# control_module register map
Vendor: Texas Instruments
Peripheral module from a debugger description file (folder am335x).
Registers are 32-bit, access per field, no defined reset value unless marked. A register's access mark holds for its fields unless they carry their own. Offsets are as the file gives them; lines under a group give offsets from that group; [hi:lo] are bit positions; {n}, {i} and the like mark numbered series; 'fields as' and 'values as' point back to an identical list; <NAME> marks a mode.

## CONTROL_MODULE (part 1 of 3)
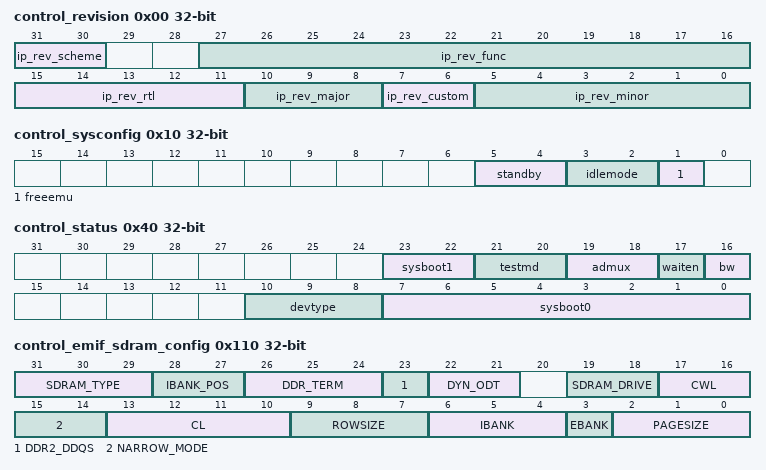
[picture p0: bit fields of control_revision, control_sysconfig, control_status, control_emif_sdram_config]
0x00 control_revision ro
  [31:30] ip_rev_scheme — 01 - New Scheme
  [27:16] ip_rev_func — Function indicates a software compatible module family. If there is no level of software compatibility a new Func number (and hence REVISION) should be assigned.
  [15:11] ip_rev_rtl — RTL Version (R).
  [10:8] ip_rev_major — Major Revision (X).
  [7:6] ip_rev_custom — Indicates a special version for a particular device. Consequence of use may avoid use of standard Chip Support Library (CSL) / Drivers - 00 = Non custom (standard) revision
  [5:0] ip_rev_minor — Minor Revision (Y).
0x04 control_hwinfo ro
  [31:0] ip_hwinfo — IP Module dependent
0x10 control_sysconfig
  [5:4] standby ro — Configure local initiator state management. Reserved in Control Module since it has no local initiator.
  [3:2] idlemode rw — Configure local target state management.
  [1] freeemu ro — Sensitivity to Emulation suspend input.
    1=en_2_0x1 (Module not sensitive to EMU suspend); 0=en_1_0x0 (Module is sensitive to EMU suspend)
0x40 control_status
  [23:22] sysboot1 rw — Used to select crystal clock frequency. See SYSBOOT Configuration Pins. Reset value is from SYSBOOT[15:14].
  [21:20] testmd rw — Set to 00b. See SYSBOOT Configuration Pins for more information. Reset value is from SYSBOOT[13:12].
  [19:18] admux rw — GPMC CS0 Default Address Muxing Reset value is from SYSBOOT[11:10].
  [17] waiten rw — GPMC CS0 Default Wait Enable See SYSBOOT Configuration Pins for more information. Reset value is from SYSBOOT[9].
    1=en_2_0x1 (Use WAIT input); 0=en_1_0x0 (Ignore WAIT input)
  [16] bw rw — GPMC CS0 Default Bus Width See SYSBOOT Configuration Pins for more information. Reset value is from SYSBOOT[8].
    1=en_2_0x1 (16-bit data bus); 0=en_1_0x0 (8-bit data bus)
  [10:8] devtype ro
  [7:0] sysboot0 rw — Selected boot mode. See SYSBOOT Configuration Pins for more information. Reset value is from SYSBOOT[7:0].
0x110 control_emif_sdram_config — The CONTROL_EMIF_SDRAM_CONFIG register exports SDRAM configuration information to the EMIF after resuming from low power scenarios. This register should be loaded with the same value as SDRAM_CONFIG during DDR initialization.
  [31:29] SDRAM_TYPE rw — SDRAM Type selection
  [28:27] IBANK_POS rw — Internal bank position.
  [26:24] DDR_TERM rw — DDR2 and DDR3 termination resistor value. Set to 0 to disable termination. For DDR2, set to 1 for 75 ohm, set to 2 for 150 ohm, and set to 3 for 50 ohm. For DDR3, set to 1 for RZQ/4, set to 2 for RZQ/2, set to 3 for RZQ/6, set to 4 for RZQ/12, and set to 5 for RZQ/8. All other values are reserved.
  [23] DDR2_DDQS rw — DDR2 differential DQS enable. Set to 0 for single ended DQS. Set to 1 for differential DQS
  [22:21] DYN_ODT rw — DDR3 Dynamic ODT. Set to 0 to turn off dynamic ODT. Set to 1 for RZQ/4 and set to 2 for RZQ/2. All other values are reserved.
  [19:18] SDRAM_DRIVE rw — SDRAM drive strength. For DDR2, set to 0 for normal, and set to 1 for weak drive strength. For DDR3, set to 0 for RZQ/6 and set to 1 for RZQ/7. For LPDDR1, set to 0 for full, set to 1 for 1/2, set to 2 for 1/4, and set to 3 for 1/8 drive strength. All other values are reserved.
  [17:16] CWL rw — DDR3 CAS Write latency. Value of 0, 1, 2, and 3 (CAS write latency of 5, 6, 7, and 8) are supported. Use the lowest value supported for best performance. All other values are reserved.
  [15:14] NARROW_MODE rw — SDRAM data bus width. Set to 0 for 32-bit and set to 1 for 16-bit. All other values are reserved.
  [13:10] CL rw — CAS Latency. The value of this field defines the CAS latency to be used when accessing connected SDRAM devices. Value of 2, 3, 4, and 5 (CAS latency of 2, 3, 4, and 5) are supported for DDR2. Value of 2, 4, 6, 8, 10, 12, and 14 (CAS latency of 5, 6, 7, 8, 9, 10, and 11) are supported for DDR3. All other values are reserved.
  [9:7] ROWSIZE rw — Row Size. Defines the number of row address bits of connected SDRAM devices. Set to 0 for 9 row bits, set to 1 for 10 row bits, set to 2 for 11 row bits, set to 3 for 12 row bits, set to 4 for 13 row bits, set to 5 for 14 row bits, set to 6 for 15 row bits, and set to 7 for 16 row bits. This field is only used when ibank_pos field in SDRAM Config register is set to 1, 2, or 3.
  [6:4] IBANK rw — Internal Bank setup. Defines number of banks inside connected SDRAM devices. Set to 0 for 1 bank, set to 1 for 2 banks, set to 2 for 4 banks, and set to 3 for 8 banks. All other values are reserved.
  [3] EBANK rw — External chip select setup. Defines whether SDRAM accesses will use 1 or 2 chip select lines. Set to 0 to use pad_cs_o_n[0] only. Set to 1 to use pad_cs_o_n[1:0].
  [2:0] PAGESIZE rw — Page Size. Defines the internal page size of connected SDRAM devices. Set to 0 for 256-word page (8 column bits), set to 1 for 512-word page (9 column bits), set to 2 for 1024-word page (10 column bits), and set to 3 for 2048-word page (11 column bits). All other values are reserved.
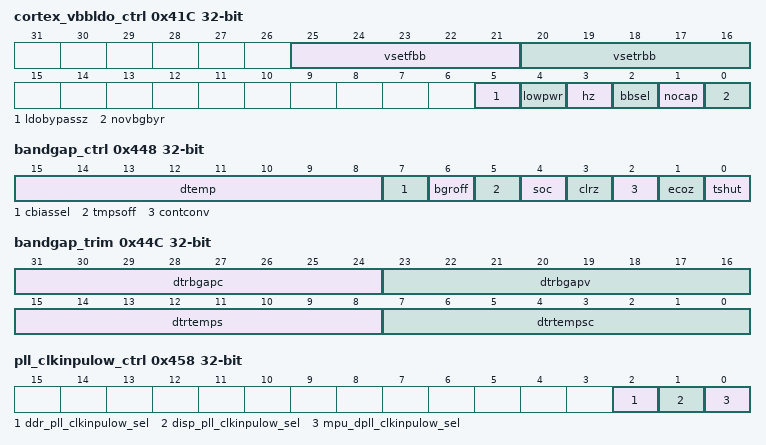
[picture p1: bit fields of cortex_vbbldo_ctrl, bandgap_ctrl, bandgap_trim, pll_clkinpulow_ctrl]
0x41C cortex_vbbldo_ctrl
  [25:21] vsetfbb rw — Trims FBB
  [20:16] vsetrbb rw — Trims RBB
  [5] ldobypassz rw — Low is bypass mode.
  [4] lowpwr rw — High enables low power mode.
  [3] hz rw — High puts vbbnw in HZ mode.
  [2] bbsel rw — High selects FBB.
  [1] nocap rw — High if external cap is not used.
  [0] novbgbyr rw — High if IREF1U is not a VBG/R current.
0x428 core_sldo_ctrl rw
  [25:16] vset — Trims VDDAR
0x42C mpu_sldo_ctrl rw
  [25:16] vset — Trims VDDAR
0x444 clk32kdivratio_ctrl
  [0] clkdivopp50_en rw
    1=en_2_0x1 (OPP50 operation, use ratio for 12MHz to 32KHz division); 0=en_1_0x0 (OPP100 operation, use ratio for 24MHz to 32KHz division)
0x448 bandgap_ctrl
  [15:8] dtemp ro — Temperature data from ADC. To be used when end of conversion (EOCZ) is 0.
  [7] cbiassel rw
    1=en_2_0x1 (Select resistor divider as reference); 0=en_1_0x0 (Select bandgap voltage as reference)
  [6] bgroff rw
    1=en_2_0x1 (Bandgap is OFF (OFF Mode)); 0=en_1_0x0 (Normal operation)
  [5] tmpsoff rw
    1=en_2_0x1 (Temperature sensor is off and thermal shutdown in OFF mode); 0=en_1_0x0 (Normal operation)
  [4] soc rw — ADC start of conversion. Transition to high starts a new ADC conversion cycle.
  [3] clrz rw — 0 = Resets the digital outputs
  [2] contconv rw
    1=en_2_0x1 (ADC continuous conversion mode); 0=en_1_0x0 (ADC single conversion mode)
  [1] ecoz ro — ADC end of conversion
    1=en_2_0x1 (Conversion in progress); 0=en_1_0x0 (End of conversion)
  [0] tshut ro
    1=en_2_0x1 (Thermal shutdown event (greater than 147C)); 0=en_1_0x0 (Normal operation)
0x44C bandgap_trim rw
  [31:24] dtrbgapc — Trim the output voltage of bandgap.
  [23:16] dtrbgapv — Trim the output voltage of bandgap.
  [15:8] dtrtemps — Trim the temperature sensor.
  [7:0] dtrtempsc — Trim the temperature sensor.
0x458 pll_clkinpulow_ctrl
  [all] fields
    1=en_2_0x1 (Select PER_CLKOUT_M2 clock as CLKINPULOW); 0=en_1_0x0 (Select CORE_CLKOUT_M6 clock as CLKINPULOW)
  [2] ddr_pll_clkinpulow_sel rw
  [1] disp_pll_clkinpulow_sel rw
  [0] mpu_dpll_clkinpulow_sel rw
0x468 mosc_ctrl
  [0] resselect rw — For oscillation with a crystal while RESSELECT is 1, an external resistor must be connected between padxi and padxo to provide bias.
    1=en_2_0x1 (Internal resistor is disconnected); 0=en_1_0x0 (1-MHz ohm resistor is connected between padxi and padxo for oscillator bias)
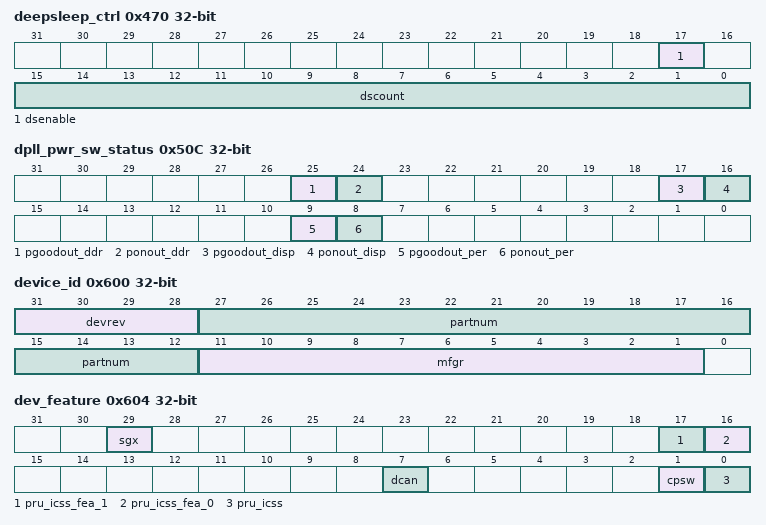
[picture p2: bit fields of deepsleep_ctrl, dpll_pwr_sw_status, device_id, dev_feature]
0x470 deepsleep_ctrl
  [17] dsenable rw — Deep sleep enable
    1=en_2_0x1 (Master oscillator output is gated); 0=en_1_0x0 (Normal operation)
  [15:0] dscount rw — Programmable count of how many CLK_M_OSC clocks needs to be seen before exiting deep sleep mode
0x50C dpll_pwr_sw_status ro
  [25] pgoodout_ddr — Power Good status for DDR DPLL
    1=en_2_0x1 (Power Good); 0=en_1_0x0 (Power Fault)
  [24] ponout_ddr — Power Enable status for DDR DPLL
    1=en_2_0x1 (Enabled); 0=en_1_0x0 (Disabled)
  [17] pgoodout_disp — Power Good status for DISP DPLL
    1=en_2_0x1 (Power Good); 0=en_1_0x0 (Power Fault)
  [16] ponout_disp — Power Enable status for DISP DPLL
    1=en_2_0x1 (Enabled); 0=en_1_0x0 (Disabled)
  [9] pgoodout_per — Power Good status for PER DPLL
    1=en_2_0x1 (Power Good); 0=en_1_0x0 (Power Fault)
  [8] ponout_per — Power Enable status for PER DPLL
    1=en_2_0x1 (Enabled); 0=en_1_0x0 (Disabled)
0x600 device_id ro
  [31:28] devrev — Device revision. 0000b = Silicon Revision 1.0. 0001b = Silicon Revision 2.0. 0010b = Silicon Revision 2.1. See device errata for detailed information on functionality in each device revision. Reset value is revision-dependent.
  [27:12] partnum — Device part number (unique JTAG ID)
  [11:1] mfgr — Manufacturer's JTAG ID
0x604 dev_feature ro
  [29] sgx — Reset value is device-dependent.
    1=en_2_0x1 (SGX enabled); 0=en_1_0x0 (3D graphics module (SGX) is disabled)
  [17] pru_icss_fea_1 — Reset value is device-dependent.
    1=en_2_0x1 (TX_AUTO_SEQUENCE enabled); 0=en_1_0x0 (TX_AUTO_SEQUENCE disabled)
  [16] pru_icss_fea_0 — Reset value is device-dependent.
    1=en_2_0x1 (EtherCAT functionality enabled, ODD_NIBBLE enabled); 0=en_1_0x0 (EtherCAT functionality disabled, ODD_NIBBLE disabled)
  [7] dcan — Reset value is device-dependent.
    1=en_2_0x1 (DCAN0, DCAN1 IPs are enabled); 0=en_1_0x0 (DCAN0, DCAN1 IPs are disabled)
  [1] cpsw — Reset value is device-dependent.
    1=en_2_0x1 (CP Switch IP (Ethernet) is enabled); 0=en_1_0x0 (CP Switch IP (Ethernet) is disabled)
  [0] pru_icss — Reset value is device-dependent.
    1=en_2_0x1 (PRU-ICSS is enabled); 0=en_1_0x0 (PRU-ICSS is disabled)
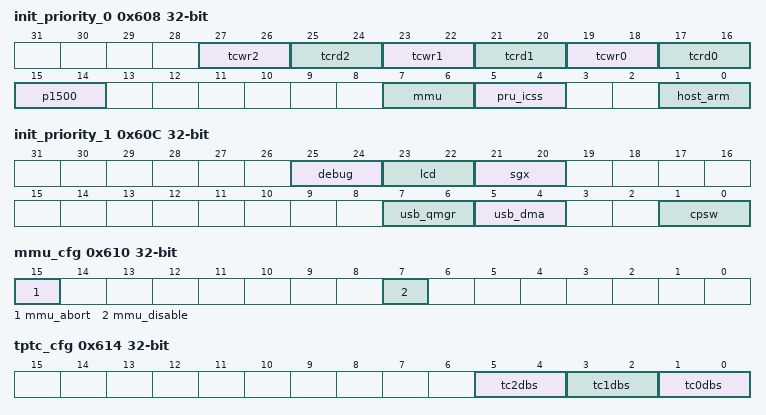
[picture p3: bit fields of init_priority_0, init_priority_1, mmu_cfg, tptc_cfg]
0x608 init_priority_0
  [27:26] tcwr2 rw — TPTC 2 Write Port initiator priority
  [25:24] tcrd2 rw — TPTC 2 Read Port initiator priority
  [23:22] tcwr1 rw — TPTC 1 Write Port initiator priority
  [21:20] tcrd1 rw — TPTC 1 Read Port initiator priority
  [19:18] tcwr0 rw — TPTC 0 Write Port initiator priority
  [17:16] tcrd0 rw — TPTC 0 Read Port initiator priority
  [15:14] p1500 rw — P1500 Port Initiator priority
  [7:6] mmu rw — System MMU initiator priority
  [5:4] pru_icss rw — PRU-ICSS initiator priority
  [1:0] host_arm rw — Host Cortex A8 initiator priority
0x60C init_priority_1
  [25:24] debug rw — Debug Subsystem initiator priority
  [23:22] lcd rw — LCD initiator priority
  [21:20] sgx rw — SGX initiator priority
  [7:6] usb_qmgr rw — USB Queue Manager initiator priority
  [5:4] usb_dma rw — USB DMA port initiator priority
  [1:0] cpsw rw — CPSW initiator priority
0x610 mmu_cfg
  [15] mmu_abort rw — MMU abort operation This bit causes the MMU to abort the current operation in case of lockup.
  [7] mmu_disable rw — MMU Disable Setting this bit disables MMU table lookup and causes accesses to use the non-translated address. This bit defaults to enabled but an identical bit within an MMU configuration register defaults to disabled and must be set after the page tables are programmed for MMU operation.
0x614 tptc_cfg
  [5:4] tc2dbs rw — TPTC2 Default Burst Size
  [3:2] tc1dbs rw — TPTC1 Default Burst Size
  [1:0] tc0dbs rw — TPTC0 Default Burst Size
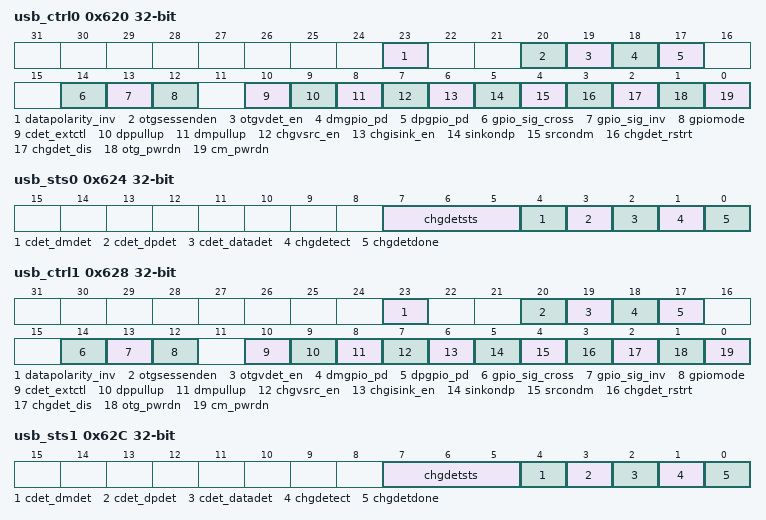
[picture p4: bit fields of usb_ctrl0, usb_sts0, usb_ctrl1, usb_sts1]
0x620 usb_ctrl0
  [23] datapolarity_inv rw — Data Polarity Invert:
    1=en_2_0x1 (DM/DP (inverted polarity of port definition)); 0=en_1_0x0 (DP/DM (normal polarity matching port definition))
  [20] otgsessenden rw — Session End Detect Enable
    1=en_2_0x1 (Turns on Session End Comparator); 0=en_1_0x0 (Disable Session End Comparator)
  [19] otgvdet_en rw — VBUS Detect Enable
    1=en_2_0x1 (Turns on all comparators except Session End comparator); 0=en_1_0x0 (Disable VBUS Detect Enable)
  [18] dmgpio_pd rw — Pulldown on DM in GPIO Mode
    1=en_2_0x1 (Disables pulldown); 0=en_1_0x0 (Enables pulldown)
  [17] dpgpio_pd rw — Pulldown on DP in GPIO Mode
    values as dmgpio_pd
  [14] gpio_sig_cross rw — UART TX -> DM UART RX -> DP
  [13] gpio_sig_inv rw — UART TX -> Invert -> DP UART RX -> Invert -> DM
  [12] gpiomode rw
    1=en_2_0x1 (GPIO Mode (UART Mode)); 0=en_1_0x0 (USB Mode)
  [10] cdet_extctl rw — Bypass the charger detection state machine
    1=en_2_0x1 (Charger detection is bypassed); 0=en_1_0x0 (Charger detection on)
  [9] dppullup rw — Pullup on DP line
    1=en_2_0x1 (Enable pullup on DP line); 0=en_1_0x0 (No effect)
  [8] dmpullup rw — Pullup on DM line
    1=en_2_0x1 (Enable pullup on DM line); 0=en_1_0x0 (No effect)
  [7] chgvsrc_en rw — Enable VSRC on DP line (Host Charger case)
  [6] chgisink_en rw — Enable ISINK on DM line (Host Charger case)
  [5] sinkondp rw
    1=en_2_0x1 (Sink on DP); 0=en_1_0x0 (Sink on DM)
  [4] srcondm rw — Source on DM
    1=en_2_0x1 (Source on DM); 0=en_1_0x0 (Source on DP)
  [3] chgdet_rstrt rw — Restart Charger Detect
  [2] chgdet_dis rw — Charger Detect Disable
    1=en_2_0x1 (Disable); 0=en_1_0x0 (Enable)
  [1] otg_pwrdn rw — Power down the USB OTG PHY
    1=en_2_0x1 (PHY Powered down); 0=en_1_0x0 (PHY in normal mode)
  [0] cm_pwrdn rw — Power down the USB CM PHY
    values as otg_pwrdn
0x624 usb_sts0 ro
  [7:5] chgdetsts — Charge Detection Status
  [4] cdet_dmdet — DM Comparator Output
  [3] cdet_dpdet — DP Comparator Output
  [2] cdet_datadet — Charger Comparator Output
  [1] chgdetect — Charger Detection Status
    1=en_2_0x1 (Charger was detected); 0=en_1_0x0 (Charger was no detected)
  [0] chgdetdone — Charger Detection Protocol Done
0x628 usb_ctrl1
  [23] datapolarity_inv rw — Data Polarity Invert:
    values as usb_ctrl0.datapolarity_inv
  [20] otgsessenden rw — Session End Detect Enable
    values as usb_ctrl0.otgsessenden
  [19] otgvdet_en rw — VBUS Detect Enable
    values as usb_ctrl0.otgvdet_en
  [18] dmgpio_pd rw — Pulldown on DM in GPIO Mode
    values as usb_ctrl0.dmgpio_pd
  [17] dpgpio_pd rw — Pulldown on DP in GPIO Mode
    values as usb_ctrl0.dmgpio_pd
  [14] gpio_sig_cross rw — UART TX -> DM UART RX -> DP
  [13] gpio_sig_inv rw — UART TX -> INV -> DP UART RX -> INV -> DM
  [12] gpiomode rw
    1=en_2_0x1 (GPIO Mode (UART)); 0=en_1_0x0 (USB Mode)
  [10] cdet_extctl rw — Bypass the charger detection state machine
    values as usb_ctrl0.cdet_extctl
  [9] dppullup rw — Pullup on DP line
    values as usb_ctrl0.dppullup
  [8] dmpullup rw — Pullup on DM line
    values as usb_ctrl0.dmpullup
  [7] chgvsrc_en rw — Enable VSRC on DP line (Host Charger case)
  [6] chgisink_en rw — Enable ISINK on DM line (Host Charger case)
  [5] sinkondp rw
    1=en_2_0x1 (Sink on DP); 0=en_1_0x0 (Sink on DM)
  [4] srcondm rw — Source on DM
    1=en_2_0x1 (Source on DM); 0=en_1_0x0 (Source on DP)
  [3] chgdet_rstrt rw — Restart Charger Detect
  [2] chgdet_dis rw — Charger Detect Disable
    1=en_2_0x1 (Disable); 0=en_1_0x0 (Enable)
  [1] otg_pwrdn rw — Power down the USB OTG PHY
    values as usb_ctrl0.otg_pwrdn
  [0] cm_pwrdn rw — Power down the USB CM PHY
    values as usb_ctrl0.otg_pwrdn
0x62C usb_sts1 ro
  fields as usb_sts0
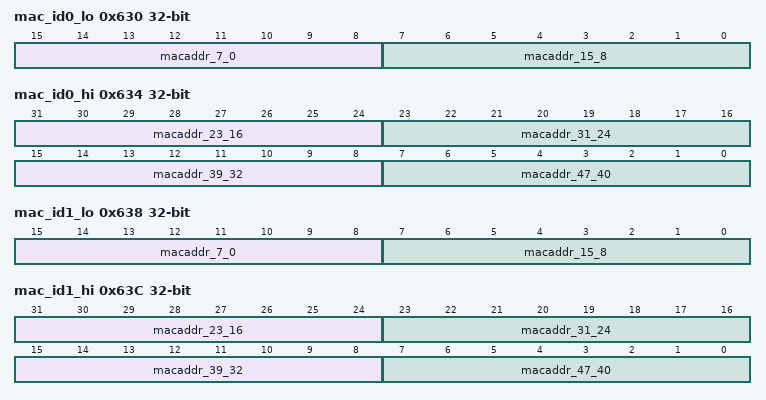
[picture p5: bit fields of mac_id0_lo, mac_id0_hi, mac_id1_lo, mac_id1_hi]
0x630 mac_id0_lo ro
  [15:8] macaddr_7_0 — MAC0 Address - Byte 0. Reset value is device-dependent.
  [7:0] macaddr_15_8 — MAC0 Address - Byte 1. Reset value is device-dependent.
0x634 mac_id0_hi ro
  [31:24] macaddr_23_16 — MAC0 Address - Byte 2. Reset value is device-dependent.
  [23:16] macaddr_31_24 — MAC0 Address - Byte 3. Reset value is device-dependent.
  [15:8] macaddr_39_32 — MAC0 Address - Byte 4. Reset value is device-dependent.
  [7:0] macaddr_47_40 — MAC0 Address - Byte 5. Reset value is device-dependent.
0x638 mac_id1_lo ro
  [15:8] macaddr_7_0 — MAC1 Address - Byte 0. Reset value is device-dependent.
  [7:0] macaddr_15_8 — MAC1 Address - Byte 1. Reset value is device-dependent.
0x63C mac_id1_hi ro
  [31:24] macaddr_23_16 — MAC1 Address - Byte 2. Reset value is device-dependent.
  [23:16] macaddr_31_24 — MAC1 Address - Byte 3. Reset value is device-dependent.
  [15:8] macaddr_39_32 — MAC1 Address - Byte 4. Reset value is device-dependent.
  [7:0] macaddr_47_40 — MAC1 Address - Byte 5. Reset value is device-dependent.
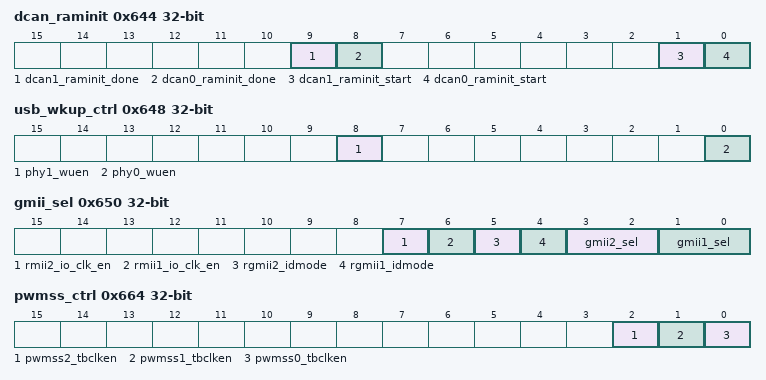
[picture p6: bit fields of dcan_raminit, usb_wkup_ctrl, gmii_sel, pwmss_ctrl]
0x644 dcan_raminit
  [9] dcan1_raminit_done ro
    1=en_2_0x1 (DCAN1 RAM Initialization complete); 0=en_1_0x0 (DCAN1 RAM Initialization NOT complete)
  [8] dcan0_raminit_done ro
    1=en_2_0x1 (DCAN0 RAM Initialization complete); 0=en_1_0x0 (DCAN0 RAM Initialization NOT complete)
  [1] dcan1_raminit_start rw — A transition from 0 to 1 will start DCAN1 RAM initialization sequence.
  [0] dcan0_raminit_start rw — A transition from 0 to 1 will start DCAN0 RAM initialization sequence.
0x648 usb_wkup_ctrl
  [8] phy1_wuen rw — PHY1 Wakeup Enable. Write to 1 enables WKUP from USB PHY1
  [0] phy0_wuen rw — PHY0 Wakeup Enable. Write to 1 enables WKUP from USB PHY0
0x650 gmii_sel
  [7] rmii2_io_clk_en rw — See "Silicon Revision Functional Differences and Enhancements" in the device manual for differences in operation based on AM335x silicon revision.
    1=en_2_0x1 (RMII Reference Clock Input mode. Enable RMII clock to be sourced from chip pin.); 0=en_1_0x0 (RMII Reference Clock Output mode. Enable RMII clock to be sourced from PLL.)
  [6] rmii1_io_clk_en rw — See "Silicon Revision Functional Differences and Enhancements" in the device manual for differences in operation based on AM335x silicon revision.
    1=en_2_0x1 (RMII Reference Clock Input mode. Enable RMII clock to be sourced from chip pin); 0=en_1_0x0 (RMII Reference Clock Output mode. Enable RMII clock to be sourced from PLL)
  [5] rgmii2_idmode rw — RGMII2 Internal Delay Mode See "Silicon Revision Functional Differences and Enhancements" in the device manual for differences in operation based on AM335x silicon revision.
    1=en_2_0x1 (No Internal Delay); 0=en_1_0x0 (Reserved)
  [4] rgmii1_idmode rw — RGMII1 Internal Delay Mode See "Silicon Revision Functional Differences and Enhancements" in the device manual for differences in operation based on AM335x silicon revision.
    1=en_2_0x1 (No Internal Delay); 0=en_1_0x0 (Reserved)
  [3:2] gmii2_sel rw
  [1:0] gmii1_sel rw
0x664 pwmss_ctrl
  [2] pwmss2_tbclken rw — Timebase clock enable for PWMSS2.
  [1] pwmss1_tbclken rw — Timebase clock enable for PWMSS1.
  [0] pwmss0_tbclken rw — Timebase clock enable for PWMSS0.
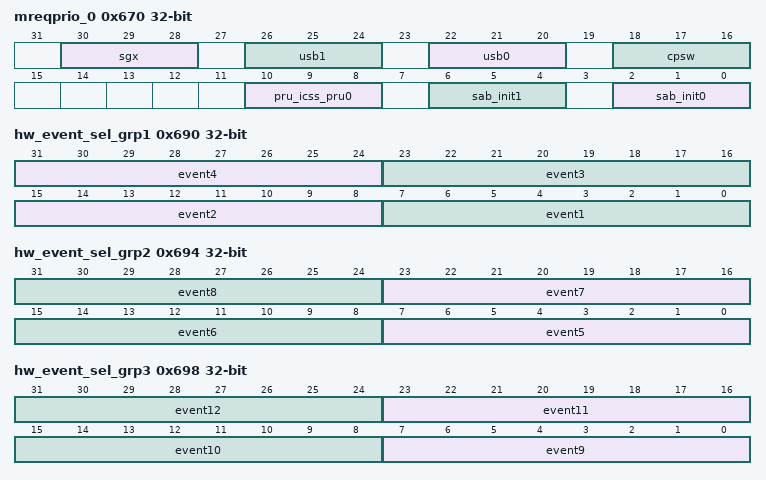
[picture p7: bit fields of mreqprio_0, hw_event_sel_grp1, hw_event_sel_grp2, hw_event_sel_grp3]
0x670 mreqprio_0
  [30:28] sgx rw — MReqPriority for SGX Initiator OCP Interface.
  [26:24] usb1 rw — MReqPriority for USB1 Initiator OCP Interface.
  [22:20] usb0 rw — MReqPriority for USB0 Initiator OCP Interface.
  [18:16] cpsw rw — MReqPriority for CPSW Initiator OCP Interface.
  [10:8] pru_icss_pru0 rw — MReqPriority for PRU-ICSS PRU0 Initiator OCP Interface.
  [6:4] sab_init1 rw — MReqPriority for MPU Initiator 1 OCP Interface.
  [2:0] sab_init0 rw — MReqPriority for MPU Initiator 0 OCP Interface.
0x674 mreqprio_1
  [2:0] exp rw — MReqPriority for Expansion Initiator OCP Interface.
0x690 hw_event_sel_grp1 rw
  [31:24] event4 — Select 4th trace event from group 1.
  [23:16] event3 — Select 3rd trace event from group 1.
  [15:8] event2 — Select 2nd trace event from group 1.
  [7:0] event1 — Select 1st trace event from group 1.
0x694 hw_event_sel_grp2 rw
  [8n-33:8n-40] event{n} (n=5..8) — Select {n}th trace event from group 2.
0x698 hw_event_sel_grp3 rw
  [8n-65:8n-72] event{n} (n=9..12) — Select {n}th trace event from group 3.
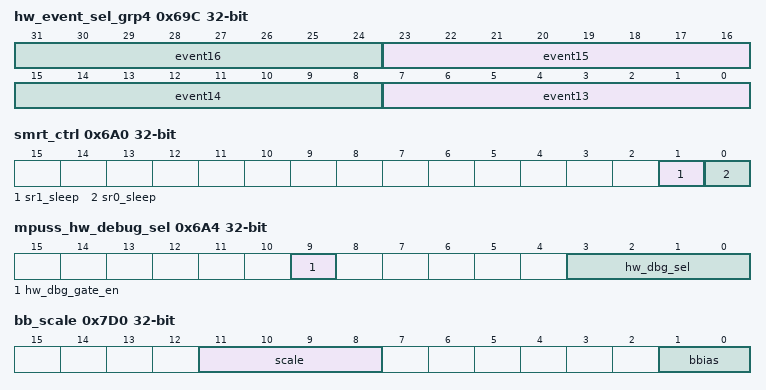
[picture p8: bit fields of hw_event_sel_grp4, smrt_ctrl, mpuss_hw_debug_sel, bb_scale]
0x69C hw_event_sel_grp4 rw
  [8n-97:8n-104] event{n} (n=13..16) — Select {n}th trace event from group 4.
0x6A0 smrt_ctrl
  [1] sr1_sleep rw
    1=en_2_0x1 (Enable sensor (SRSLEEP on sensor driven to 0).); 0=en_1_0x0 (Disable sensor (SRSLEEP on sensor driven to 1))
  [0] sr0_sleep rw
    values as sr1_sleep
0x6A4 mpuss_hw_debug_sel
  [9] hw_dbg_gate_en rw — To save power input to MPUSS_HW_DBG_INFO is gated off to all zeros when HW_DBG_GATE_EN bit is low.
    1=en_2_0x1 (Debug info not gated off); 0=en_1_0x0 (Debug info gated off)
  [3:0] hw_dbg_sel rw — Selects which Group of signals are sent out to the MODENA_HW_DBG_INFO register. Please see MPU functional specification for more details.
0x6A8 mpuss_hw_dbg_info ro
  [31:0] hw_dbg_info — Hardware Debug Info from MPU.
0x770 vdd_mpu_opp_050 ro
  [23:0] ntarget — Ntarget value for MPU Voltage domain OPP50. Reset value is device-dependent.
0x774 vdd_mpu_opp_100 ro
  [23:0] ntarget — Ntarget value for MPU Voltage domain OPP100. Reset value is device-dependent.
0x778 vdd_mpu_opp_120 ro
  [23:0] ntarget — Ntarget value for MPU Voltage domain OPP120. Reset value is device-dependent.
0x77C vdd_mpu_opp_turbo ro
  [23:0] ntarget — Ntarget value for MPU Voltage domain OPPTURBO. Reset value is device-dependent.
0x7B8 vdd_core_opp_050 ro
  [23:0] ntarget — Ntarget value for CORE Voltage domain OPP50. Reset value is device-dependent.
0x7BC vdd_core_opp_100 ro
  [23:0] ntarget — Ntarget value for CORE Voltage domain OPP100. Reset value is device-dependent.
0x7D0 bb_scale ro
  [11:8] scale — Dynamic core voltage scaling for class 0.
  [1:0] bbias — BBIAS value from Efuse.
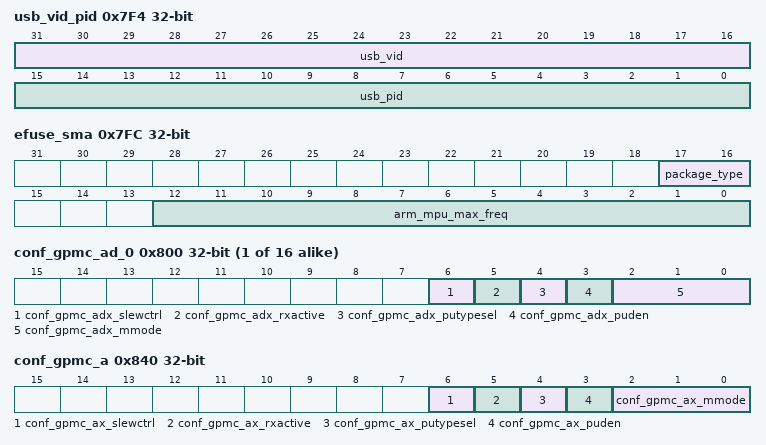
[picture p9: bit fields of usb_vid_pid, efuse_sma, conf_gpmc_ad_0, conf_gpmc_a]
0x7F4 usb_vid_pid ro
  [31:16] usb_vid — USB Vendor ID.
  [15:0] usb_pid — USB Product ID.
0x7FC efuse_sma ro — This register describes the device's ARM maximum frequency capabilities and package type. Note that this register is only applicable in PG2.x. The contents of this register is not applicable in PG1.0 devices.
  [17:16] package_type — Designates the Package type of the device (PG2.x only). Reset is package-dependent. 00b = Undefined. 01b = ZCZ Package. 10b = ZCE Package. 11b = Reserved.
  [12:0] arm_mpu_max_freq — Designates the ARM MPU Maximum Frequency supported by the device (PG2.x only). Reset is device-dependent. There are also voltage requirements that accompany each frequency (OPPs). See the device specific data manual for this information and for information on device variants. 0x1FEF = 300 MHz ARM MPU Maximum (ZCZ Package only). 0x1FAF = 600 MHz ARM MPU Maximum (ZCZ Package only). 0x1F2F = 720 MHz ARM MPU Maximum (ZCZ Package only). 0x1E2F = 800 MHz ARM MPU Maximum (ZCZ Package only). 0x1C2F = 1 GHz ARM MPU Maximum (ZCZ Package only). 0x1FDF = 300 MHz ARM MPU Maximum (ZCE Package only). 0x1F9F = 600 MHz ARM MPU Maximum (ZCE Package only). All other values are reserved.
{0x800+4i} conf_gpmc_ad_{i} (i=0..15) — See the device datasheet for information on default pin mux configurations. Note that the device ROM may change the default pin mux for certain pins based on the SYSBOOT mode settings.
  [6] conf_gpmc_adx_slewctrl rw — Select between faster or slower slew rate , value X Reset value is pad-dependent.
    1=en_2_0x1 (Slow); 0=en_1_0x0 (Fast)
  [5] conf_gpmc_adx_rxactive rw — Input enable value for the PAD
    1=en_2_0x1 (Receiver enabled); 0=en_1_0x0 (Receiver disabled)
  [4] conf_gpmc_adx_putypesel rw — Pad pullup/pulldown type selection, value X Reset value is pad-dependent.
    1=en_2_0x1 (Pullup selected); 0=en_1_0x0 (Pulldown selected)
  [3] conf_gpmc_adx_puden rw — Reset value is pad-dependent.
    1=en_2_0x1 (Pullup/pulldown disabled); 0=en_1_0x0 (Pullup/pulldown enabled)
  [2:0] conf_gpmc_adx_mmode rw — Pad functional signal mux select, value X Reset value is pad-dependent.
0x840 conf_gpmc_a
  [6] conf_gpmc_ax_slewctrl rw — Select between faster or slower slew rate , value X Reset value is pad-dependent.
    1=en_2_0x1 (Slow); 0=en_1_0x0 (Fast)
  [5] conf_gpmc_ax_rxactive rw — Input enable value for the PAD
    values as conf_gpmc_ad_0.conf_gpmc_adx_rxactive
  [4] conf_gpmc_ax_putypesel rw — Pad pullup/pulldown type selection, Value X Reset value is pad-dependent.
    1=en_2_0x1 (Pullup selected); 0=en_1_0x0 (Pulldown selected)
  [3] conf_gpmc_ax_puden rw — Pad pullup/pulldown enable, value X Reset value is pad-dependent.
    values as conf_gpmc_ad_0.conf_gpmc_adx_puden
  [2:0] conf_gpmc_ax_mmode rw — Pad functional signal mux select, value X Reset value is pad-dependent.
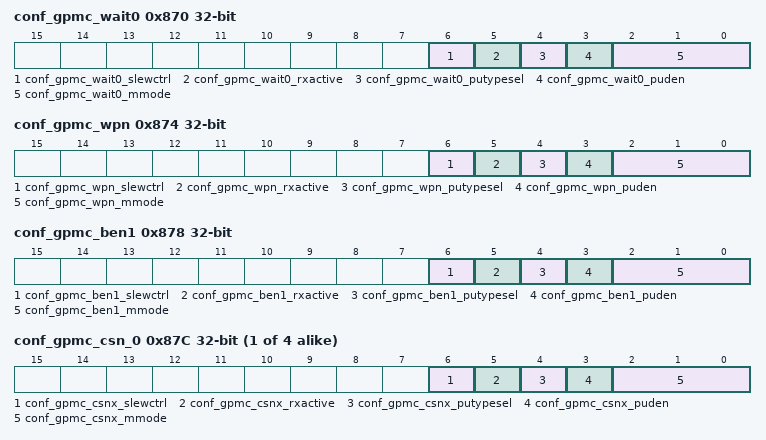
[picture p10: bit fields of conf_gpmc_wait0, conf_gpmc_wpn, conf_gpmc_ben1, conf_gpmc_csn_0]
0x870 conf_gpmc_wait0
  [6] conf_gpmc_wait0_slewctrl rw — Select between faster or slower slew rate , value X Reset value is pad-dependent.
    1=en_2_0x1 (Slow); 0=en_1_0x0 (Fast)
  [5] conf_gpmc_wait0_rxactive rw — Input enable value for the PAD
    values as conf_gpmc_ad_0.conf_gpmc_adx_rxactive
  [4] conf_gpmc_wait0_putypesel rw — Pad pullup/pulldown type selection, Value X Reset value is pad-dependent.
    1=en_2_0x1 (Pullup selected); 0=en_1_0x0 (Pulldown selected)
  [3] conf_gpmc_wait0_puden rw — Pad pullup/pulldown enable, value X Reset value is pad-dependent.
    values as conf_gpmc_ad_0.conf_gpmc_adx_puden
  [2:0] conf_gpmc_wait0_mmode rw — Pad functional signal mux select, value X Reset value is pad-dependent.
0x874 conf_gpmc_wpn
  [6] conf_gpmc_wpn_slewctrl rw — Select between faster or slower slew rate , value X Reset value is pad-dependent.
    1=en_2_0x1 (Slow); 0=en_1_0x0 (Fast)
  [5] conf_gpmc_wpn_rxactive rw — Input enable value for the PAD
    values as conf_gpmc_ad_0.conf_gpmc_adx_rxactive
  [4] conf_gpmc_wpn_putypesel rw — Pad pullup/pulldown type selection, Value X Reset value is pad-dependent.
    1=en_2_0x1 (Pullup selected); 0=en_1_0x0 (Pulldown selected)
  [3] conf_gpmc_wpn_puden rw — Pad pullup/pulldown enable, value X Reset value is pad-dependent.
    values as conf_gpmc_ad_0.conf_gpmc_adx_puden
  [2:0] conf_gpmc_wpn_mmode rw — Pad functional signal mux select, value X Reset value is pad-dependent.
0x878 conf_gpmc_ben1 — See the device datasheet for information on default pin mux configurations. Note that the device ROM may change the default pin mux for certain pins based on the SYSBOOT mode settings.
  [6] conf_gpmc_ben1_slewctrl rw — Select between faster or slower slew rate Reset value is pad-dependent.
    1=en_2_0x1 (Slow); 0=en_1_0x0 (Fast)
  [5] conf_gpmc_ben1_rxactive rw — Input enable value for the PAD
    values as conf_gpmc_ad_0.conf_gpmc_adx_rxactive
  [4] conf_gpmc_ben1_putypesel rw — Pad pullup/pulldown type selection Reset value is pad-dependent.
    1=en_2_0x1 (Pullup selected); 0=en_1_0x0 (Pulldown selected)
  [3] conf_gpmc_ben1_puden rw — Pad pullup/pulldown enable Reset value is pad-dependent.
    values as conf_gpmc_ad_0.conf_gpmc_adx_puden
  [2:0] conf_gpmc_ben1_mmode rw — Pad functional signal mux select. Reset value is pad-dependent.
{0x87C+4i} conf_gpmc_csn_{i} (i=0..3) — See the device datasheet for information on default pin mux configurations. Note that the device ROM may change the default pin mux for certain pins based on the SYSBOOT mode settings.
  [6] conf_gpmc_csnx_slewctrl rw — Select between faster or slower slew rate Reset value is pad-dependent.
    1=en_2_0x1 (Slow); 0=en_1_0x0 (Fast)
  [5] conf_gpmc_csnx_rxactive rw — Input enable value for the PAD
    values as conf_gpmc_ad_0.conf_gpmc_adx_rxactive
  [4] conf_gpmc_csnx_putypesel rw — Pad pullup/pulldown type selection Reset value is pad-dependent.
    1=en_2_0x1 (Pullup selected); 0=en_1_0x0 (Pulldown selected)
  [3] conf_gpmc_csnx_puden rw — Pad pullup/pulldown enable Reset value is pad-dependent.
    values as conf_gpmc_ad_0.conf_gpmc_adx_puden
  [2:0] conf_gpmc_csnx_mmode rw — Pad functional signal mux select. Reset value is pad-dependent.
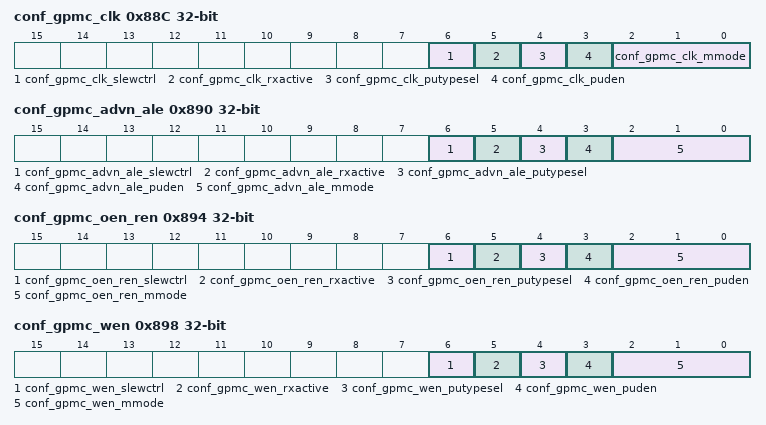
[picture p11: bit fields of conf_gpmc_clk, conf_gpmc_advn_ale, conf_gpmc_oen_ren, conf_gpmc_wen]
0x88C conf_gpmc_clk — See the device datasheet for information on default pin mux configurations. Note that the device ROM may change the default pin mux for certain pins based on the SYSBOOT mode settings.
  [6] conf_gpmc_clk_slewctrl rw — Select between faster or slower slew rate Reset value is pad-dependent.
    1=en_2_0x1 (Slow); 0=en_1_0x0 (Fast)
  [5] conf_gpmc_clk_rxactive rw — Input enable value for the PAD
    values as conf_gpmc_ad_0.conf_gpmc_adx_rxactive
  [4] conf_gpmc_clk_putypesel rw — Pad pullup/pulldown type selection Reset value is pad-dependent.
    1=en_2_0x1 (Pullup selected); 0=en_1_0x0 (Pulldown selected)
  [3] conf_gpmc_clk_puden rw — Pad pullup/pulldown enable Reset value is pad-dependent.
    values as conf_gpmc_ad_0.conf_gpmc_adx_puden
  [2:0] conf_gpmc_clk_mmode rw — Pad functional signal mux select. Reset value is pad-dependent.
0x890 conf_gpmc_advn_ale — See the device datasheet for information on default pin mux configurations. Note that the device ROM may change the default pin mux for certain pins based on the SYSBOOT mode settings.
  [6] conf_gpmc_advn_ale_slewctrl rw — Select between faster or slower slew rate Reset value is pad-dependent.
    1=en_2_0x1 (Slow); 0=en_1_0x0 (Fast)
  [5] conf_gpmc_advn_ale_rxactive rw — Input enable value for the PAD
    values as conf_gpmc_ad_0.conf_gpmc_adx_rxactive
  [4] conf_gpmc_advn_ale_putypesel rw — Pad pullup/pulldown type selection Reset value is pad-dependent.
    1=en_2_0x1 (Pullup selected); 0=en_1_0x0 (Pulldown selected)
  [3] conf_gpmc_advn_ale_puden rw — Pad pullup/pulldown enable Reset value is pad-dependent.
    values as conf_gpmc_ad_0.conf_gpmc_adx_puden
  [2:0] conf_gpmc_advn_ale_mmode rw — Pad functional signal mux select. Reset value is pad-dependent.
0x894 conf_gpmc_oen_ren — See the device datasheet for information on default pin mux configurations. Note that the device ROM may change the default pin mux for certain pins based on the SYSBOOT mode settings.
  [6] conf_gpmc_oen_ren_slewctrl rw — Select between faster or slower slew rate Reset value is pad-dependent.
    1=en_2_0x1 (Slow); 0=en_1_0x0 (Fast)
  [5] conf_gpmc_oen_ren_rxactive rw — Input enable value for the PAD
    values as conf_gpmc_ad_0.conf_gpmc_adx_rxactive
  [4] conf_gpmc_oen_ren_putypesel rw — Pad pullup/pulldown type selection Reset value is pad-dependent.
    1=en_2_0x1 (Pullup selected); 0=en_1_0x0 (Pulldown selected)
  [3] conf_gpmc_oen_ren_puden rw — Pad pullup/pulldown enable Reset value is pad-dependent.
    values as conf_gpmc_ad_0.conf_gpmc_adx_puden
  [2:0] conf_gpmc_oen_ren_mmode rw — Pad functional signal mux select. Reset value is pad-dependent.
0x898 conf_gpmc_wen — See the device datasheet for information on default pin mux configurations. Note that the device ROM may change the default pin mux for certain pins based on the SYSBOOT mode settings.
  [6] conf_gpmc_wen_slewctrl rw — Select between faster or slower slew rate Reset value is pad-dependent.
    1=en_2_0x1 (Slow); 0=en_1_0x0 (Fast)
  [5] conf_gpmc_wen_rxactive rw — Input enable value for the PAD
    values as conf_gpmc_ad_0.conf_gpmc_adx_rxactive
  [4] conf_gpmc_wen_putypesel rw — Pad pullup/pulldown type selection Reset value is pad-dependent.
    1=en_2_0x1 (Pullup selected); 0=en_1_0x0 (Pulldown selected)
  [3] conf_gpmc_wen_puden rw — Pad pullup/pulldown enable Reset value is pad-dependent.
    values as conf_gpmc_ad_0.conf_gpmc_adx_puden
  [2:0] conf_gpmc_wen_mmode rw — Pad functional signal mux select. Reset value is pad-dependent.
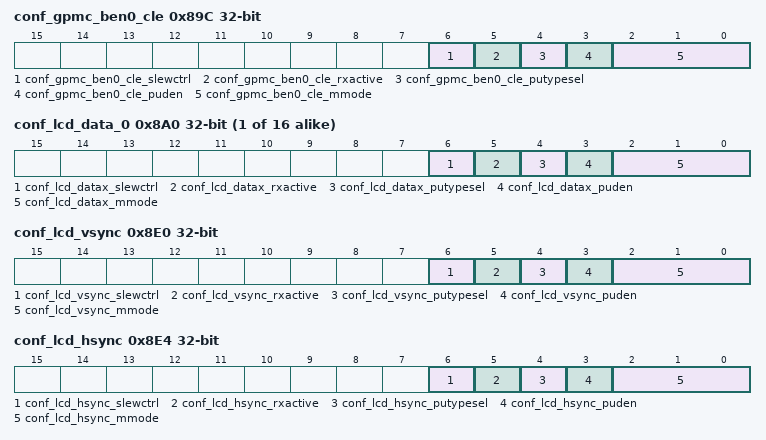
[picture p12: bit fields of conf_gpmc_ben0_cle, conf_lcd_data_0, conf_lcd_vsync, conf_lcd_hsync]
0x89C conf_gpmc_ben0_cle — See the device datasheet for information on default pin mux configurations. Note that the device ROM may change the default pin mux for certain pins based on the SYSBOOT mode settings.
  [6] conf_gpmc_ben0_cle_slewctrl rw — Select between faster or slower slew rate Reset value is pad-dependent.
    1=en_2_0x1 (Slow); 0=en_1_0x0 (Fast)
  [5] conf_gpmc_ben0_cle_rxactive rw — Input enable value for the PAD
    values as conf_gpmc_ad_0.conf_gpmc_adx_rxactive
  [4] conf_gpmc_ben0_cle_putypesel rw — Pad pullup/pulldown type selection Reset value is pad-dependent.
    1=en_2_0x1 (Pullup selected); 0=en_1_0x0 (Pulldown selected)
  [3] conf_gpmc_ben0_cle_puden rw — Pad pullup/pulldown enable Reset value is pad-dependent.
    values as conf_gpmc_ad_0.conf_gpmc_adx_puden
  [2:0] conf_gpmc_ben0_cle_mmode rw — Pad functional signal mux select. Reset value is pad-dependent.
{0x8A0+4i} conf_lcd_data_{i} (i=0..15) — See the device datasheet for information on default pin mux configurations. Note that the device ROM may change the default pin mux for certain pins based on the SYSBOOT mode settings.
  [6] conf_lcd_datax_slewctrl rw — Select between faster or slower slew rate Reset value is pad-dependent.
    1=en_2_0x1 (Slow); 0=en_1_0x0 (Fast)
  [5] conf_lcd_datax_rxactive rw — Input enable value for the PAD
    values as conf_gpmc_ad_0.conf_gpmc_adx_rxactive
  [4] conf_lcd_datax_putypesel rw — Pad pullup/pulldown type selection Reset value is pad-dependent.
    1=en_2_0x1 (Pullup selected); 0=en_1_0x0 (Pulldown selected)
  [3] conf_lcd_datax_puden rw — Pad pullup/pulldown enable Reset value is pad-dependent.
    values as conf_gpmc_ad_0.conf_gpmc_adx_puden
  [2:0] conf_lcd_datax_mmode rw — Pad functional signal mux select. Reset value is pad-dependent.
0x8E0 conf_lcd_vsync — See the device datasheet for information on default pin mux configurations. Note that the device ROM may change the default pin mux for certain pins based on the SYSBOOT mode settings.
  [6] conf_lcd_vsync_slewctrl rw — Select between faster or slower slew rate Reset value is pad-dependent.
    1=en_2_0x1 (Slow); 0=en_1_0x0 (Fast)
  [5] conf_lcd_vsync_rxactive rw — Input enable value for the PAD
    values as conf_gpmc_ad_0.conf_gpmc_adx_rxactive
  [4] conf_lcd_vsync_putypesel rw — Pad pullup/pulldown type selection Reset value is pad-dependent.
    1=en_2_0x1 (Pullup selected); 0=en_1_0x0 (Pulldown selected)
  [3] conf_lcd_vsync_puden rw — Pad pullup/pulldown enable Reset value is pad-dependent.
    values as conf_gpmc_ad_0.conf_gpmc_adx_puden
  [2:0] conf_lcd_vsync_mmode rw — Pad functional signal mux select. Reset value is pad-dependent.
0x8E4 conf_lcd_hsync — See the device datasheet for information on default pin mux configurations. Note that the device ROM may change the default pin mux for certain pins based on the SYSBOOT mode settings.
  [6] conf_lcd_hsync_slewctrl rw — Select between faster or slower slew rate Reset value is pad-dependent.
    1=en_2_0x1 (Slow); 0=en_1_0x0 (Fast)
  [5] conf_lcd_hsync_rxactive rw — Input enable value for the PAD
    values as conf_gpmc_ad_0.conf_gpmc_adx_rxactive
  [4] conf_lcd_hsync_putypesel rw — Pad pullup/pulldown type selection Reset value is pad-dependent.
    1=en_2_0x1 (Pullup selected); 0=en_1_0x0 (Pulldown selected)
  [3] conf_lcd_hsync_puden rw — Pad pullup/pulldown enable Reset value is pad-dependent.
    values as conf_gpmc_ad_0.conf_gpmc_adx_puden
  [2:0] conf_lcd_hsync_mmode rw — Pad functional signal mux select. Reset value is pad-dependent.
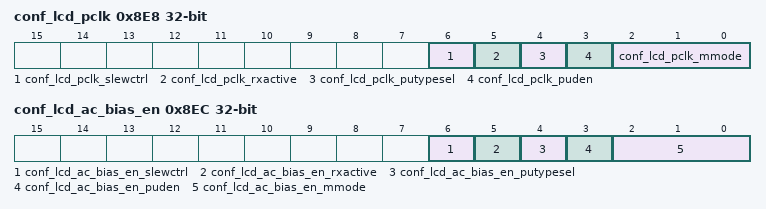
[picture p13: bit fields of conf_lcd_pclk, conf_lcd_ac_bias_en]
0x8E8 conf_lcd_pclk — See the device datasheet for information on default pin mux configurations. Note that the device ROM may change the default pin mux for certain pins based on the SYSBOOT mode settings.
  [6] conf_lcd_pclk_slewctrl rw — Select between faster or slower slew rate Reset value is pad-dependent.
    1=en_2_0x1 (Slow); 0=en_1_0x0 (Fast)
  [5] conf_lcd_pclk_rxactive rw — Input enable value for the PAD
    values as conf_gpmc_ad_0.conf_gpmc_adx_rxactive
  [4] conf_lcd_pclk_putypesel rw — Pad pullup/pulldown type selection Reset value is pad-dependent.
    1=en_2_0x1 (Pullup selected); 0=en_1_0x0 (Pulldown selected)
  [3] conf_lcd_pclk_puden rw — Pad pullup/pulldown enable Reset value is pad-dependent.
    values as conf_gpmc_ad_0.conf_gpmc_adx_puden
  [2:0] conf_lcd_pclk_mmode rw — Pad functional signal mux select. Reset value is pad-dependent.
0x8EC conf_lcd_ac_bias_en — See the device datasheet for information on default pin mux configurations. Note that the device ROM may change the default pin mux for certain pins based on the SYSBOOT mode settings.
  [6] conf_lcd_ac_bias_en_slewctrl rw — Select between faster or slower slew rate Reset value is pad-dependent.
    1=en_2_0x1 (Slow); 0=en_1_0x0 (Fast)
  [5] conf_lcd_ac_bias_en_rxactive rw — Input enable value for the PAD
    values as conf_gpmc_ad_0.conf_gpmc_adx_rxactive
  [4] conf_lcd_ac_bias_en_putypesel rw — Pad pullup/pulldown type selection Reset value is pad-dependent.
    1=en_2_0x1 (Pullup selected); 0=en_1_0x0 (Pulldown selected)
  [3] conf_lcd_ac_bias_en_puden rw — Pad pullup/pulldown enable Reset value is pad-dependent.
    values as conf_gpmc_ad_0.conf_gpmc_adx_puden
  [2:0] conf_lcd_ac_bias_en_mmode rw — Pad functional signal mux select. Reset value is pad-dependent.
